# DSC28034 register map
Vendor: Beijing Haawking Technology Co.,Ltd.; File version: 1.0
Registers are 32-bit, read-write, reset 0x0 unless marked. A register's access mark holds for its fields unless they carry their own. Offsets are from the block's base; [hi:lo] are bit positions; {n}, {i} and the like mark numbered series; 'fields as' and 'values as' point back to an identical list.

## SYSCTL — System Controller
Base 0x50440000
0x00 git_id — Git short commit id
0x04 clk_freq — System clock base frequency
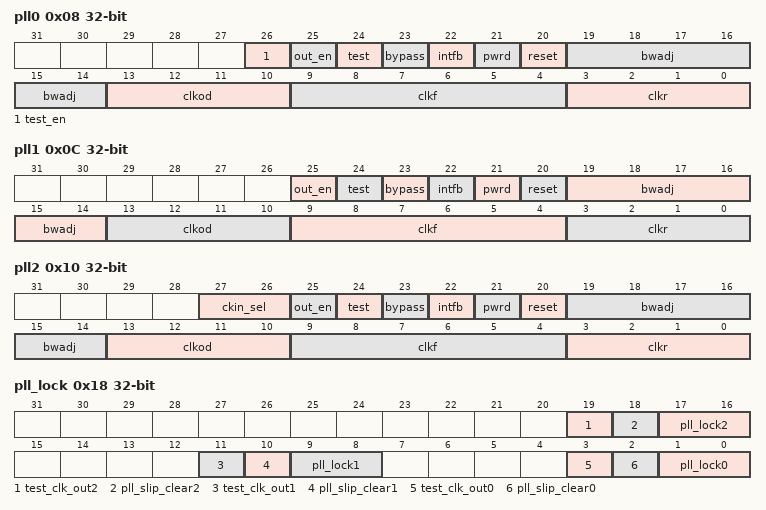
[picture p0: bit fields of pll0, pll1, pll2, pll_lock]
0x08 pll0 — PLL0 controller
  [26] test_en, [25] out_en, [24] test, [23] bypass, [22] intfb, [21] pwrd, [20] reset, [19:14] bwadj, [13:10] clkod, [9:4] clkf, [3:0] clkr
0x0C pll1 — PLL1 controller
  [25] out_en, [24] test, [23] bypass, [22] intfb, [21] pwrd, [20] reset, [19:14] bwadj, [13:10] clkod, [9:4] clkf, [3:0] clkr
0x10 pll2 — PLL2 controller
  [27:26] ckin_sel, [25] out_en, [24] test, [23] bypass, [22] intfb, [21] pwrd, [20] reset, [19:14] bwadj, [13:10] clkod, [9:4] clkf, [3:0] clkr
0x18 pll_lock — PLL lock tester
  [19] test_clk_out2, [18] pll_slip_clear2, [17:16] pll_lock2, [11] test_clk_out1, [10] pll_slip_clear1, [9:8] pll_lock1, [3] test_clk_out0, [2] pll_slip_clear0, [1:0] pll_lock0
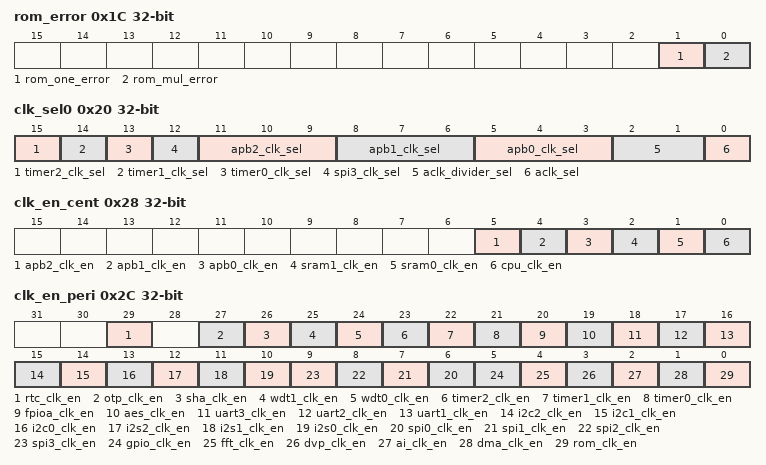
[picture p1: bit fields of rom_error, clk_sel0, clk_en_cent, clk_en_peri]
0x1C rom_error — AXI ROM detector
  [1] rom_one_error, [0] rom_mul_error
0x20 clk_sel0 — Clock select controller 0
  [15] timer2_clk_sel, [14] timer1_clk_sel, [13] timer0_clk_sel, [12] spi3_clk_sel, [11:9] apb2_clk_sel, [8:6] apb1_clk_sel, [5:3] apb0_clk_sel, [2:1] aclk_divider_sel, [0] aclk_sel
0x24 clk_sel1 — Clock select controller 1
  [0] spi3_sample_clk_sel
0x28 clk_en_cent — Central clock enable
  [5] apb2_clk_en, [4] apb1_clk_en, [3] apb0_clk_en, [2] sram1_clk_en, [1] sram0_clk_en, [0] cpu_clk_en
0x2C clk_en_peri — Peripheral clock enable
  [29] rtc_clk_en, [27] otp_clk_en, [26] sha_clk_en, [25] wdt1_clk_en, [24] wdt0_clk_en, [23] timer2_clk_en, [22] timer1_clk_en, [21] timer0_clk_en, [20] fpioa_clk_en, [19] aes_clk_en, [18] uart3_clk_en, [17] uart2_clk_en, [16] uart1_clk_en, [15] i2c2_clk_en, [14] i2c1_clk_en, [13] i2c0_clk_en, [12] i2s2_clk_en, [11] i2s1_clk_en, [10] i2s0_clk_en, [n+6] spi{n}_clk_en (n=0..3), [5] gpio_clk_en, [4] fft_clk_en, [3] dvp_clk_en, [2] ai_clk_en, [1] dma_clk_en, [0] rom_clk_en
0x30 soft_reset — Soft reset ctrl
  [0] soft_reset
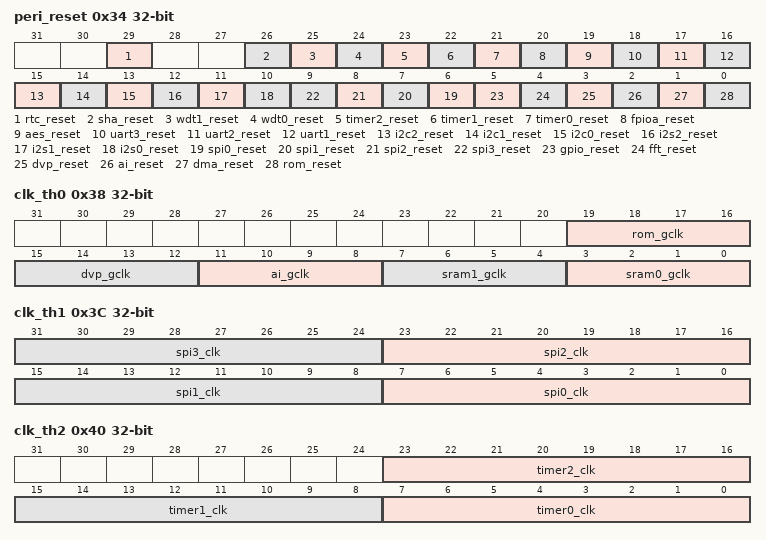
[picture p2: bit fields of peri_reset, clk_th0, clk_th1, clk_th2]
0x34 peri_reset — Peripheral reset controller
  [29] rtc_reset, [26] sha_reset, [25] wdt1_reset, [24] wdt0_reset, [23] timer2_reset, [22] timer1_reset, [21] timer0_reset, [20] fpioa_reset, [19] aes_reset, [18] uart3_reset, [17] uart2_reset, [16] uart1_reset, [15] i2c2_reset, [14] i2c1_reset, [13] i2c0_reset, [12] i2s2_reset, [11] i2s1_reset, [10] i2s0_reset, [n+6] spi{n}_reset (n=0..3), [5] gpio_reset, [4] fft_reset, [3] dvp_reset, [2] ai_reset, [1] dma_reset, [0] rom_reset
0x38 clk_th0 — Clock threshold controller 0
  [19:16] rom_gclk, [15:12] dvp_gclk, [11:8] ai_gclk, [7:4] sram1_gclk, [3:0] sram0_gclk
0x3C clk_th1 — Clock threshold controller 1
  [8n+7:8n] spi{n}_clk (n=0..3)
0x40 clk_th2 — Clock threshold controller 2
  [23:16] timer2_clk, [15:8] timer1_clk, [7:0] timer0_clk
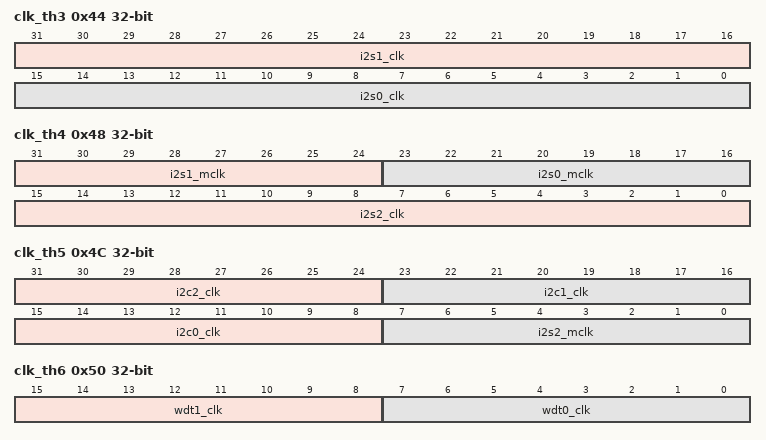
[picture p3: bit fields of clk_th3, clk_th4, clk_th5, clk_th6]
0x44 clk_th3 — Clock threshold controller 3
  [31:16] i2s1_clk, [15:0] i2s0_clk
0x48 clk_th4 — Clock threshold controller 4
  [31:24] i2s1_mclk, [23:16] i2s0_mclk, [15:0] i2s2_clk
0x4C clk_th5 — Clock threshold controller 5
  [31:24] i2c2_clk, [23:16] i2c1_clk, [15:8] i2c0_clk, [7:0] i2s2_mclk
0x50 clk_th6 — Clock threshold controller 6
  [15:8] wdt1_clk, [7:0] wdt0_clk
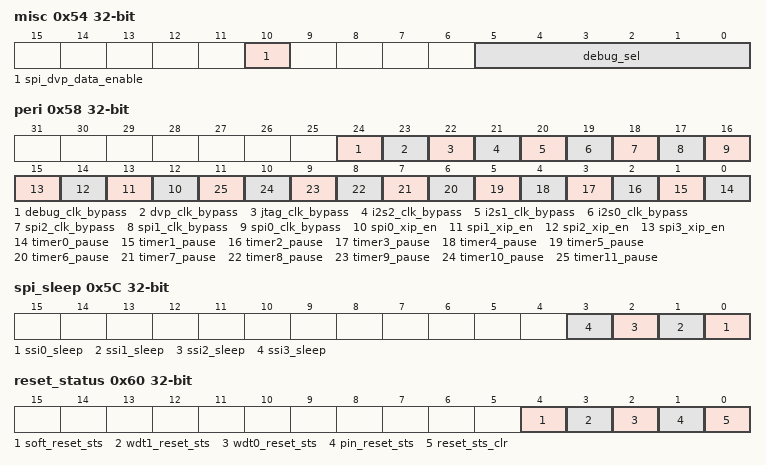
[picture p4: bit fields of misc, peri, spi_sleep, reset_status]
0x54 misc — Miscellaneous controller
  [10] spi_dvp_data_enable, [5:0] debug_sel
0x58 peri — Peripheral controller
  [24] debug_clk_bypass, [23] dvp_clk_bypass, [22] jtag_clk_bypass, [21] i2s2_clk_bypass, [20] i2s1_clk_bypass, [19] i2s0_clk_bypass, [18] spi2_clk_bypass, [17] spi1_clk_bypass, [16] spi0_clk_bypass, [n+12] spi{n}_xip_en (n=0..3), [n] timer{n}_pause (n=0..11)
0x5C spi_sleep — SPI sleep controller
  [n] ssi{n}_sleep (n=0..3)
0x60 reset_status — Reset source status
  [4] soft_reset_sts, [3] wdt1_reset_sts, [2] wdt0_reset_sts, [1] pin_reset_sts, [0] reset_sts_clr
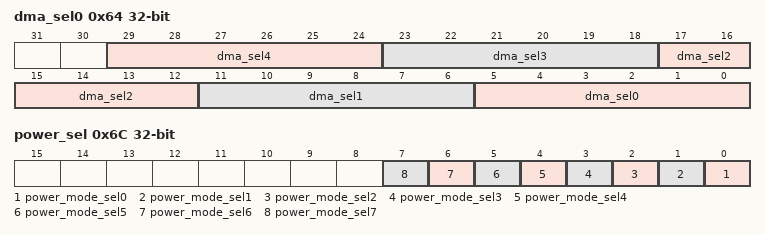
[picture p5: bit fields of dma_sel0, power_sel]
0x64 dma_sel0 — DMA handshake selector
  [all] fields
    0=ssi0_rx_req; 1=ssi0_tx_req; 2=ssi1_rx_req; 3=ssi1_tx_req; 4=ssi2_rx_req; 5=ssi2_tx_req; 6=ssi3_rx_req; 7=ssi3_tx_req; 8=i2c0_rx_req; 9=i2c0_tx_req; 10=i2c1_rx_req; 11=i2c1_tx_req; 12=i2c2_rx_req; 13=i2c2_tx_req; 14=uart1_rx_req; 15=uart1_tx_req; 16=uart2_rx_req; 17=uart2_tx_req; 18=uart3_rx_req; 19=uart3_tx_req; 20=aes_req; 21=sha_rx_req; 22=ai_rx_req; 23=fft_rx_req; 24=fft_tx_req; 25=i2s0_tx_req; 26=i2s0_rx_req; 27=i2s1_tx_req; 28=i2s1_rx_req; 29=i2s2_tx_req; 30=i2s2_rx_req; 31=i2s0_bf_dir_req; 32=i2s0_bf_voice_req
  [6n+5:6n] dma_sel{n} (n=0..4)
0x68 dma_sel1 — DMA handshake selector
  [5:0] dma_sel5
    values as the fields of dma_sel0
0x6C power_sel — IO Power Mode Select controller
  [n] power_mode_sel{n} (n=0..7)
